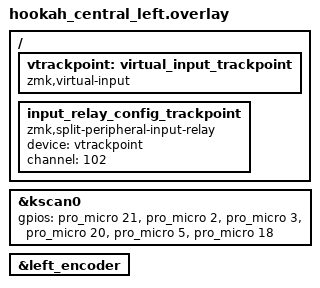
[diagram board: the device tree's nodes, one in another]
#include "hookah.dtsi"

&kscan0
{
    col - gpios = <&pro_micro 21 GPIO_ACTIVE_HIGH>, <&pro_micro 2 GPIO_ACTIVE_HIGH>, <&pro_micro 3 GPIO_ACTIVE_HIGH>, <&pro_micro 20 GPIO_ACTIVE_HIGH>, <&pro_micro 5 GPIO_ACTIVE_HIGH>, <&pro_micro 18 GPIO_ACTIVE_HIGH>;
};

&left_encoder
{
    status = "okay";
};

/
{
vtrackpoint:
    virtual_input_trackpoint
    {
        compatible = "zmk,virtual-input";
    };

    input_relay_config_trackpoint
    {
        compatible = "zmk,split-peripheral-input-relay";
        device = <&vtrackpoint>;
        relay - channel = <102>;
    };
};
